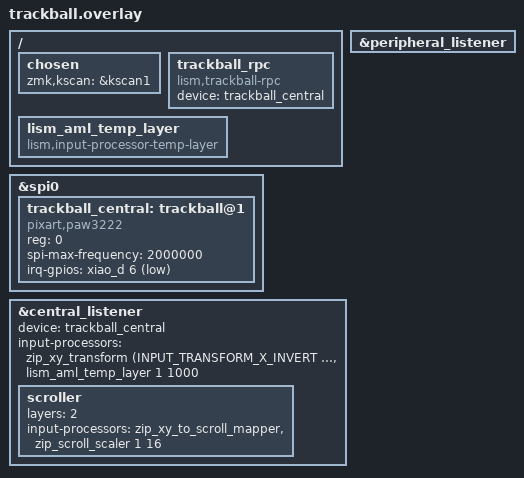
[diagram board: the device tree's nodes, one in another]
/ {
    chosen {
        zmk,kscan = &kscan1;
    };
};

&spi0 {
    status = "okay";

    trackball_central: trackball@1 {
        status = "okay";
        compatible = "pixart,paw3222";
        reg = <0>;
        spi-max-frequency = <2000000>;
        irq-gpios = <&xiao_d 6 (GPIO_ACTIVE_LOW | GPIO_PULL_UP)>;
    };
};

// ペリフェラル（split経由）のリスナーを有効化
&peripheral_listener {
    status = "okay";
};

// セントラルのリスナーを有効化し、deviceを紐付け
&central_listener {
    status = "okay";
    device = <&trackball_central>;
    input-processors =
        <&zip_xy_transform (INPUT_TRANSFORM_X_INVERT | INPUT_TRANSFORM_Y_INVERT)>,
        <&lism_aml_temp_layer 1 1000>;

    scroller {
        layers = <2>;
        input-processors =
            <&zip_xy_to_scroll_mapper>,
            <&zip_scroll_scaler 1 16>;
    };
};

// LisMアプリからのライブ設定用RPCサービス（トラックボール感度・スクロール方向・AML閾値）
/ {
    trackball_rpc: trackball_rpc {
        compatible = "lism,trackball-rpc";
        status = "okay";
        device = <&trackball_central>;
    };

    // オートマチックマウスレイヤー: トラックボール操作中はMouse Layer(1)を
    // 一時的に有効化し、一定時間操作がなければ自動的に戻る。
    // 待機時間(param2の1000はプレースホルダ)はLisMアプリからその場で変更可能。
    lism_aml_temp_layer: lism_aml_temp_layer {
        compatible = "lism,input-processor-temp-layer";
        #input-processor-cells = <2>;
        status = "okay";
    };
};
